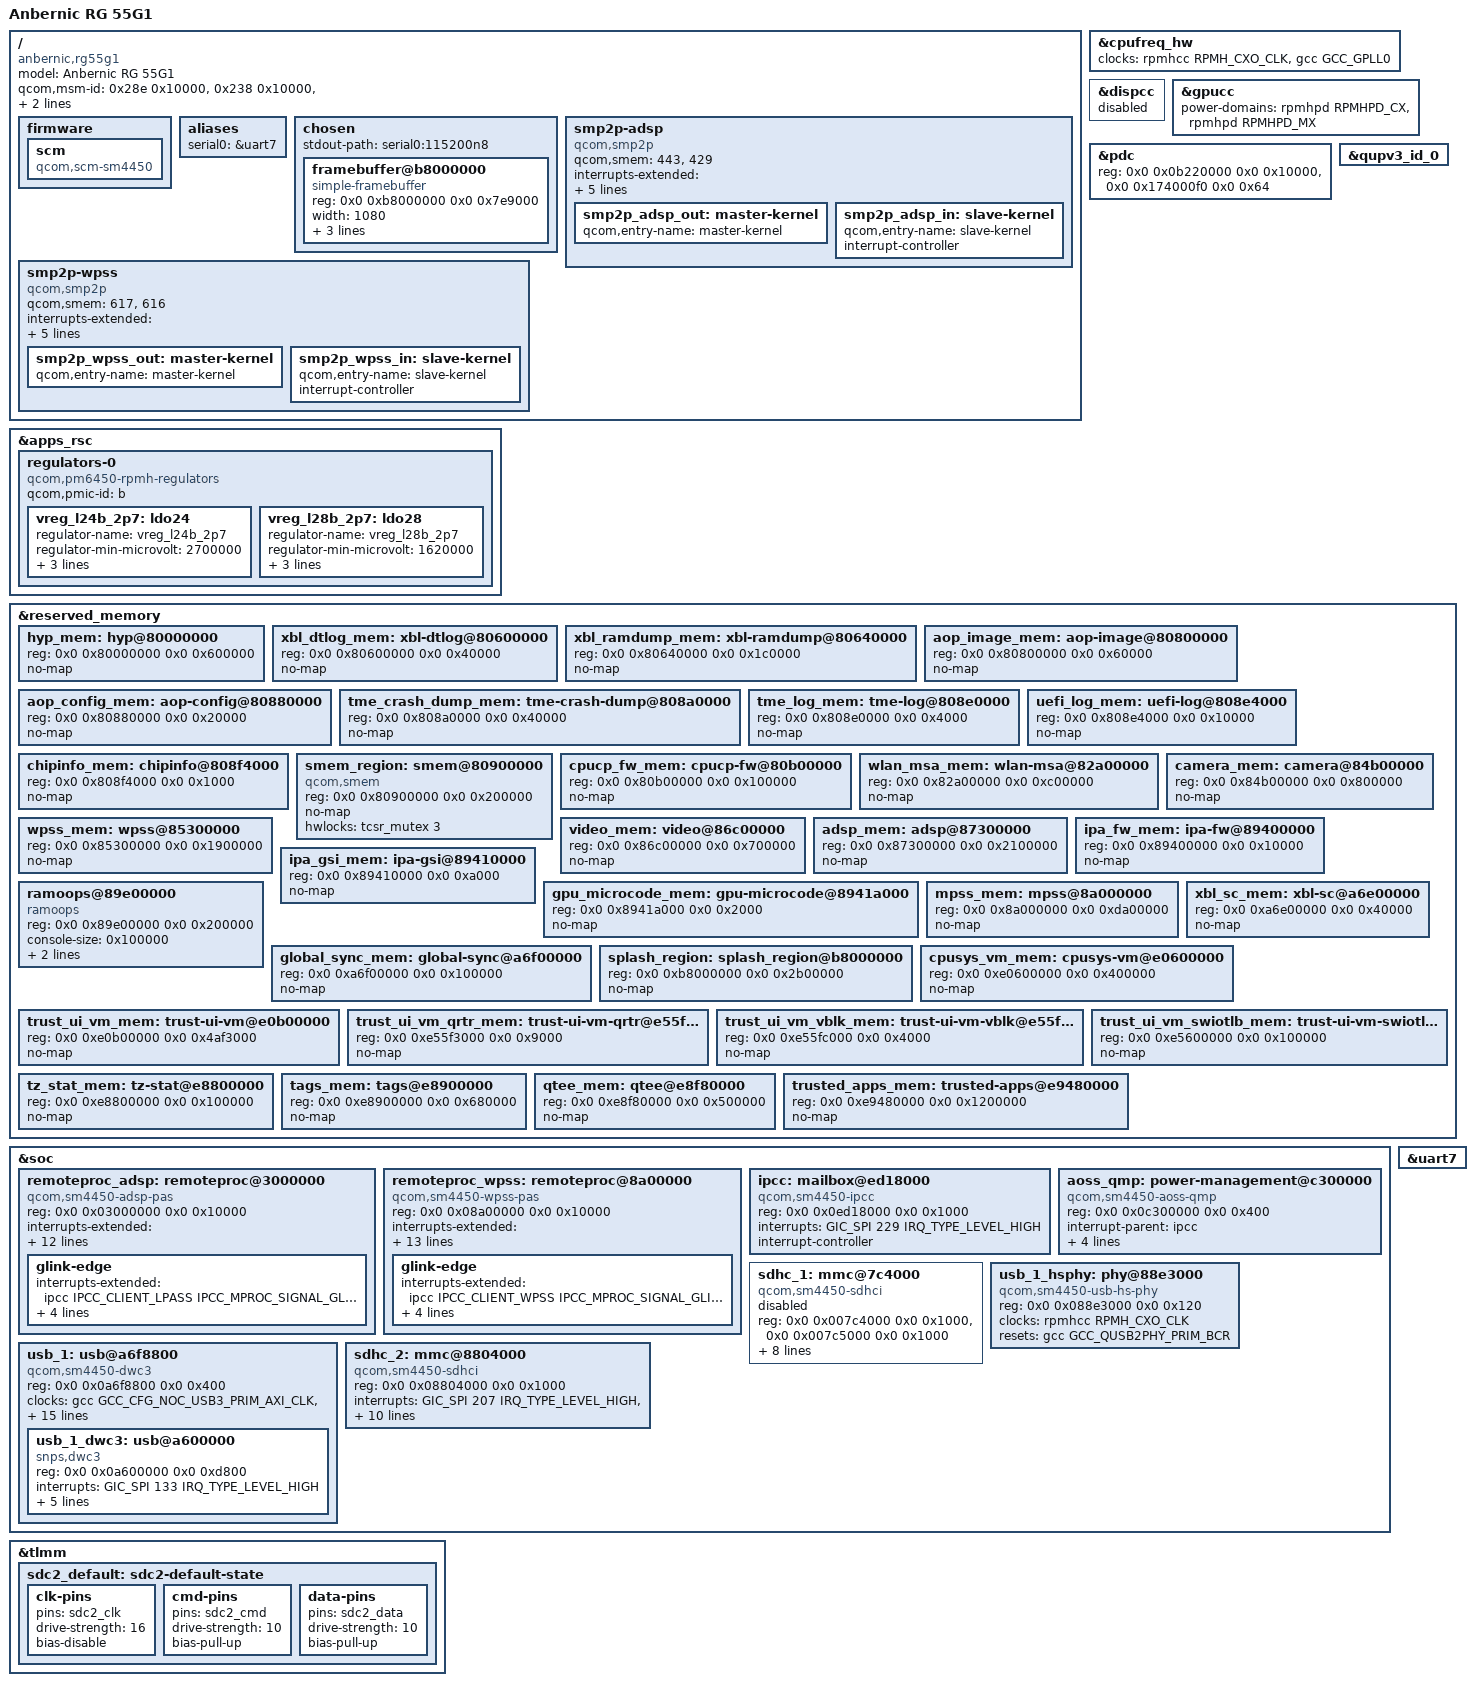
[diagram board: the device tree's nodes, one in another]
// SPDX-License-Identifier: BSD-3-Clause
/*
 * Anbernic RG 55G1 (SM4450)
 *
 * Hardware data from the stock DT in lualiliu's
 * RG55G1 linux tree (sg4250p-anbernic-rg55g1.dts, decompiled vendor DTB).
 */

/dts-v1/;

#include <dt-bindings/gpio/gpio.h>
#include <dt-bindings/mailbox/qcom-ipcc.h>
#include <dt-bindings/regulator/qcom,rpmh-regulator.h>
#include "sm4450.dtsi"
/ {
	model = "Anbernic RG 55G1";
	compatible = "anbernic,rg55g1", "qcom,sm4450";
	qcom,msm-id = <0x28e 0x10000>, <0x238 0x10000>, <0x25a 0x10000>;
	qcom,board-id = <0x1000b 0>;

	firmware {
		scm: scm {
			compatible = "qcom,scm-sm4450", "qcom,scm";
		};
	};

	aliases {
		serial0 = &uart7;
	};

	chosen {
		#address-cells = <2>;
		#size-cells = <2>;
		ranges;
		stdout-path = "serial0:115200n8";

		framebuffer@b8000000 {
			compatible = "simple-framebuffer";
			reg = <0x0 0xb8000000 0x0 0x7e9000>;
			width = <1080>;
			height = <1920>;
			stride = <4320>;
			format = "x8r8g8b8";
			status = "okay";
		};
	};

	smp2p-adsp {
		compatible = "qcom,smp2p";
		qcom,smem = <443>, <429>;
		interrupts-extended = <&ipcc IPCC_CLIENT_LPASS
					     IPCC_MPROC_SIGNAL_SMP2P
					     IRQ_TYPE_EDGE_RISING>;
		mboxes = <&ipcc IPCC_CLIENT_LPASS IPCC_MPROC_SIGNAL_SMP2P>;
		qcom,local-pid = <0>;
		qcom,remote-pid = <2>;

		smp2p_adsp_out: master-kernel {
			qcom,entry-name = "master-kernel";
			#qcom,smem-state-cells = <1>;
		};

		smp2p_adsp_in: slave-kernel {
			qcom,entry-name = "slave-kernel";
			interrupt-controller;
			#interrupt-cells = <2>;
		};
	};

	smp2p-wpss {
		compatible = "qcom,smp2p";
		qcom,smem = <617>, <616>;
		interrupts-extended = <&ipcc IPCC_CLIENT_WPSS
					     IPCC_MPROC_SIGNAL_SMP2P
					     IRQ_TYPE_EDGE_RISING>;
		mboxes = <&ipcc IPCC_CLIENT_WPSS IPCC_MPROC_SIGNAL_SMP2P>;
		qcom,local-pid = <0>;
		qcom,remote-pid = <13>;

		smp2p_wpss_out: master-kernel {
			qcom,entry-name = "master-kernel";
			#qcom,smem-state-cells = <1>;
		};

		smp2p_wpss_in: slave-kernel {
			qcom,entry-name = "slave-kernel";
			interrupt-controller;
			#interrupt-cells = <2>;
		};
	};
};

&apps_rsc {
	regulators-0 {
		compatible = "qcom,pm6450-rpmh-regulators";
		qcom,pmic-id = "b";

		vreg_l24b_2p7: ldo24 {
			regulator-name = "vreg_l24b_2p7";
			regulator-min-microvolt = <2700000>;
			regulator-max-microvolt = <3544000>;
			regulator-initial-mode = <RPMH_REGULATOR_MODE_HPM>;
		};

		vreg_l28b_2p7: ldo28 {
			regulator-name = "vreg_l28b_2p7";
			regulator-min-microvolt = <1620000>;
			regulator-max-microvolt = <3300000>;
			regulator-initial-mode = <RPMH_REGULATOR_MODE_HPM>;
		};
	};
};

&cpufreq_hw {
	clocks = <&rpmhcc RPMH_CXO_CLK>, <&gcc GCC_GPLL0>;
};

/* TODO: revert this dispcc */
&dispcc {
	status = "disabled";
};

&gpucc {
	power-domains = <&rpmhpd RPMHPD_CX>,
			<&rpmhpd RPMHPD_MX>;
};

&pdc {
	reg = <0x0 0x0b220000 0x0 0x10000>, <0x0 0x174000f0 0x0 0x64>;
};

&qupv3_id_0 {
	status = "okay";
};

&reserved_memory {
	hyp_mem: hyp@80000000 {
		reg = <0x0 0x80000000 0x0 0x600000>;
		no-map;
	};

	xbl_dtlog_mem: xbl-dtlog@80600000 {
		reg = <0x0 0x80600000 0x0 0x40000>;
		no-map;
	};

	xbl_ramdump_mem: xbl-ramdump@80640000 {
		reg = <0x0 0x80640000 0x0 0x1c0000>;
		no-map;
	};

	aop_image_mem: aop-image@80800000 {
		reg = <0x0 0x80800000 0x0 0x60000>;
		no-map;
	};

	aop_config_mem: aop-config@80880000 {
		reg = <0x0 0x80880000 0x0 0x20000>;
		no-map;
	};

	tme_crash_dump_mem: tme-crash-dump@808a0000 {
		reg = <0x0 0x808a0000 0x0 0x40000>;
		no-map;
	};

	tme_log_mem: tme-log@808e0000 {
		reg = <0x0 0x808e0000 0x0 0x4000>;
		no-map;
	};

	uefi_log_mem: uefi-log@808e4000 {
		reg = <0x0 0x808e4000 0x0 0x10000>;
		no-map;
	};

	chipinfo_mem: chipinfo@808f4000 {
		reg = <0x0 0x808f4000 0x0 0x1000>;
		no-map;
	};

	smem_region: smem@80900000 {
		compatible = "qcom,smem";
		reg = <0x0 0x80900000 0x0 0x200000>;
		no-map;
		hwlocks = <&tcsr_mutex 3>;
	};

	cpucp_fw_mem: cpucp-fw@80b00000 {
		reg = <0x0 0x80b00000 0x0 0x100000>;
		no-map;
	};

	wlan_msa_mem: wlan-msa@82a00000 {
		reg = <0x0 0x82a00000 0x0 0xc00000>;
		no-map;
	};

	camera_mem: camera@84b00000 {
		reg = <0x0 0x84b00000 0x0 0x800000>;
		no-map;
	};

	wpss_mem: wpss@85300000 {
		reg = <0x0 0x85300000 0x0 0x1900000>;
		no-map;
	};

	video_mem: video@86c00000 {
		reg = <0x0 0x86c00000 0x0 0x700000>;
		no-map;
	};

	adsp_mem: adsp@87300000 {
		reg = <0x0 0x87300000 0x0 0x2100000>;
		no-map;
	};

	ipa_fw_mem: ipa-fw@89400000 {
		reg = <0x0 0x89400000 0x0 0x10000>;
		no-map;
	};

	ipa_gsi_mem: ipa-gsi@89410000 {
		reg = <0x0 0x89410000 0x0 0xa000>;
		no-map;
	};

	gpu_microcode_mem: gpu-microcode@8941a000 {
		reg = <0x0 0x8941a000 0x0 0x2000>;
		no-map;
	};

	ramoops@89e00000 {
		compatible = "ramoops";
		reg = <0x0 0x89e00000 0x0 0x200000>;
		console-size = <0x100000>;
		record-size = <0x20000>;
		pmsg-size = <0x20000>;
	};

	mpss_mem: mpss@8a000000 {
		reg = <0x0 0x8a000000 0x0 0xda00000>;
		no-map;
	};

	xbl_sc_mem: xbl-sc@a6e00000 {
		reg = <0x0 0xa6e00000 0x0 0x40000>;
		no-map;
	};

	global_sync_mem: global-sync@a6f00000 {
		reg = <0x0 0xa6f00000 0x0 0x100000>;
		no-map;
	};

	splash_region: splash_region@b8000000 {
		reg = <0x0 0xb8000000 0x0 0x2b00000>;
		no-map;
	};

	cpusys_vm_mem: cpusys-vm@e0600000 {
		reg = <0x0 0xe0600000 0x0 0x400000>;
		no-map;
	};

	trust_ui_vm_mem: trust-ui-vm@e0b00000 {
		reg = <0x0 0xe0b00000 0x0 0x4af3000>;
		no-map;
	};

	trust_ui_vm_qrtr_mem: trust-ui-vm-qrtr@e55f3000 {
		reg = <0x0 0xe55f3000 0x0 0x9000>;
		no-map;
	};

	trust_ui_vm_vblk_mem: trust-ui-vm-vblk@e55fc000 {
		reg = <0x0 0xe55fc000 0x0 0x4000>;
		no-map;
	};

	trust_ui_vm_swiotlb_mem: trust-ui-vm-swiotlb@e5600000 {
		reg = <0x0 0xe5600000 0x0 0x100000>;
		no-map;
	};

	tz_stat_mem: tz-stat@e8800000 {
		reg = <0x0 0xe8800000 0x0 0x100000>;
		no-map;
	};

	tags_mem: tags@e8900000 {
		reg = <0x0 0xe8900000 0x0 0x680000>;
		no-map;
	};

	qtee_mem: qtee@e8f80000 {
		reg = <0x0 0xe8f80000 0x0 0x500000>;
		no-map;
	};

	trusted_apps_mem: trusted-apps@e9480000 {
		reg = <0x0 0xe9480000 0x0 0x1200000>;
		no-map;
	};
};

&soc {
	remoteproc_adsp: remoteproc@3000000 {
		compatible = "qcom,sm4450-adsp-pas";
		reg = <0x0 0x03000000 0x0 0x10000>;

		interrupts-extended = <&pdc 6 IRQ_TYPE_EDGE_RISING>,
				      <&smp2p_adsp_in 0 IRQ_TYPE_EDGE_RISING>,
				      <&smp2p_adsp_in 1 IRQ_TYPE_EDGE_RISING>,
				      <&smp2p_adsp_in 2 IRQ_TYPE_EDGE_RISING>,
				      <&smp2p_adsp_in 3 IRQ_TYPE_EDGE_RISING>;
		interrupt-names = "wdog", "fatal", "ready",
				  "handover", "stop-ack";

		clocks = <&rpmhcc RPMH_CXO_CLK>;
		clock-names = "xo";

		power-domains = <&rpmhpd RPMHPD_CX>;
		power-domain-names = "cx";

		memory-region = <&adsp_mem>;

		qcom,qmp = <&aoss_qmp>;
		qcom,smem-states = <&smp2p_adsp_out 0>;
		qcom,smem-state-names = "stop";

		firmware-name = "qcom/sm4450/adsp.mbn";

		/* TODO: audio - stock uses AudioReach (gpr/q6apm), no
		 * mainline sm4450 machine driver yet */
		glink-edge {
			interrupts-extended = <&ipcc IPCC_CLIENT_LPASS
						     IPCC_MPROC_SIGNAL_GLINK_QMP
						     IRQ_TYPE_EDGE_RISING>;
			mboxes = <&ipcc IPCC_CLIENT_LPASS
					IPCC_MPROC_SIGNAL_GLINK_QMP>;
			label = "lpass";
			qcom,remote-pid = <2>;
		};
	};

	remoteproc_wpss: remoteproc@8a00000 {
		compatible = "qcom,sm4450-wpss-pas";
		reg = <0x0 0x08a00000 0x0 0x10000>;

		interrupts-extended = <&intc GIC_SPI 587 IRQ_TYPE_EDGE_RISING>,
				      <&smp2p_wpss_in 0 IRQ_TYPE_EDGE_RISING>,
				      <&smp2p_wpss_in 1 IRQ_TYPE_EDGE_RISING>,
				      <&smp2p_wpss_in 2 IRQ_TYPE_EDGE_RISING>,
				      <&smp2p_wpss_in 3 IRQ_TYPE_EDGE_RISING>;
		interrupt-names = "wdog", "fatal", "ready",
				  "handover", "stop-ack";

		clocks = <&rpmhcc RPMH_CXO_CLK>;
		clock-names = "xo";

		power-domains = <&rpmhpd RPMHPD_CX>,
				<&rpmhpd RPMHPD_MX>;
		power-domain-names = "cx", "mx";

		memory-region = <&wpss_mem>;

		qcom,qmp = <&aoss_qmp>;
		qcom,smem-states = <&smp2p_wpss_out 0>;
		qcom,smem-state-names = "stop";

		firmware-name = "qcom/sm4450/wpss.mbn";

		/* TODO: ath11k WCN6750 (?) node */
		glink-edge {
			interrupts-extended = <&ipcc IPCC_CLIENT_WPSS
						     IPCC_MPROC_SIGNAL_GLINK_QMP
						     IRQ_TYPE_EDGE_RISING>;
			mboxes = <&ipcc IPCC_CLIENT_WPSS
					IPCC_MPROC_SIGNAL_GLINK_QMP>;
			label = "wpss";
			qcom,remote-pid = <13>;
		};
	};

	ipcc: mailbox@ed18000 {
		compatible = "qcom,sm4450-ipcc", "qcom,ipcc";
		reg = <0x0 0x0ed18000 0x0 0x1000>;
		interrupts = <GIC_SPI 229 IRQ_TYPE_LEVEL_HIGH>;
		interrupt-controller;
		#interrupt-cells = <3>;
		#mbox-cells = <2>;
	};

	aoss_qmp: power-management@c300000 {
		compatible = "qcom,sm4450-aoss-qmp", "qcom,aoss-qmp";
		reg = <0x0 0x0c300000 0x0 0x400>;
		interrupt-parent = <&ipcc>;
		interrupts-extended = <&ipcc IPCC_CLIENT_AOP
					     IPCC_MPROC_SIGNAL_GLINK_QMP
					     IRQ_TYPE_EDGE_RISING>;
		mboxes = <&ipcc IPCC_CLIENT_AOP IPCC_MPROC_SIGNAL_GLINK_QMP>;
		#clock-cells = <0>;
	};

	sdhc_1: mmc@7c4000 {
		compatible = "qcom,sm4450-sdhci", "qcom,sdhci-msm-v5";
		reg = <0x0 0x007c4000 0x0 0x1000>,
		      <0x0 0x007c5000 0x0 0x1000>;
		reg-names = "hc", "cqhci";
		interrupts = <GIC_SPI 135 IRQ_TYPE_LEVEL_HIGH>,
			     <GIC_SPI 137 IRQ_TYPE_LEVEL_HIGH>;
		interrupt-names = "hc_irq", "pwr_irq";
		clocks = <&gcc GCC_SDCC1_AHB_CLK>,
			 <&gcc GCC_SDCC1_APPS_CLK>,
			 <&rpmhcc RPMH_CXO_CLK>;
		clock-names = "iface", "core", "xo";
		power-domains = <&rpmhpd RPMHPD_CX>;
		bus-width = <8>;
		supports-cqe;
		non-removable;
		status = "disabled";
	};

	usb_1_hsphy: phy@88e3000 {
		compatible = "qcom,sm4450-usb-hs-phy",
			     "qcom,usb-snps-hs-7nm-phy";
		reg = <0x0 0x088e3000 0x0 0x120>;
		#phy-cells = <0>;
		clocks = <&rpmhcc RPMH_CXO_CLK>;
		clock-names = "ref";
		resets = <&gcc GCC_QUSB2PHY_PRIM_BCR>;
	};

	usb_1: usb@a6f8800 {
		compatible = "qcom,sm4450-dwc3", "qcom,dwc3";
		reg = <0x0 0x0a6f8800 0x0 0x400>;
		#address-cells = <2>;
		#size-cells = <2>;
		ranges;

		clocks = <&gcc GCC_CFG_NOC_USB3_PRIM_AXI_CLK>,
			 <&gcc GCC_USB30_PRIM_MASTER_CLK>,
			 <&gcc GCC_AGGRE_USB3_PRIM_AXI_CLK>,
			 <&gcc GCC_USB30_PRIM_SLEEP_CLK>,
			 <&gcc GCC_USB30_PRIM_MOCK_UTMI_CLK>;
		clock-names = "cfg_noc",
			      "core",
			      "iface",
			      "sleep",
			      "mock_utmi";

		assigned-clocks = <&gcc GCC_USB30_PRIM_MOCK_UTMI_CLK>,
				  <&gcc GCC_USB30_PRIM_MASTER_CLK>;
		assigned-clock-rates = <19200000>, <133333333>;

		interrupts-extended = <&intc GIC_SPI 130 IRQ_TYPE_LEVEL_HIGH>,
				      <&pdc 14 IRQ_TYPE_EDGE_BOTH>,
				      <&pdc 15 IRQ_TYPE_EDGE_BOTH>,
				      <&pdc 17 IRQ_TYPE_LEVEL_HIGH>;
		interrupt-names = "pwr_event",
				  "dp_hs_phy_irq",
				  "dm_hs_phy_irq",
				  "ss_phy_irq";

		power-domains = <&gcc GCC_USB30_PRIM_GDSC>;

		resets = <&gcc GCC_USB30_PRIM_BCR>;

		usb_1_dwc3: usb@a600000 {
			compatible = "snps,dwc3";
			reg = <0x0 0x0a600000 0x0 0xd800>;
			interrupts = <GIC_SPI 133 IRQ_TYPE_LEVEL_HIGH>;
			snps,dis_u2_susphy_quirk;
			snps,dis_enblslpm_quirk;
			phys = <&usb_1_hsphy>;
			phy-names = "usb2-phy";
			/* TODO: HS only for now */
			maximum-speed = "high-speed";
			/* TODO: role switch via tcpm once PD controller is wired */
			dr_mode = "peripheral";
		};
	};

	sdhc_2: mmc@8804000 {
		compatible = "qcom,sm4450-sdhci", "qcom,sdhci-msm-v5";
		reg = <0x0 0x08804000 0x0 0x1000>;
		reg-names = "hc";
		interrupts = <GIC_SPI 207 IRQ_TYPE_LEVEL_HIGH>,
			     <GIC_SPI 223 IRQ_TYPE_LEVEL_HIGH>;
		interrupt-names = "hc_irq", "pwr_irq";
		clocks = <&gcc GCC_SDCC2_AHB_CLK>,
			 <&gcc GCC_SDCC2_APPS_CLK>,
			 <&rpmhcc RPMH_CXO_CLK>;
		clock-names = "iface", "core", "xo";
		power-domains = <&rpmhpd RPMHPD_CX>;
		pinctrl-0 = <&sdc2_default>;
		pinctrl-names = "default";
		vmmc-supply = <&vreg_l24b_2p7>;
		vqmmc-supply = <&vreg_l28b_2p7>;
		bus-width = <4>;
		cd-gpios = <&tlmm 101 GPIO_ACTIVE_LOW>;
		no-sdio;
		status = "okay";
	};
};

&tlmm {
	sdc2_default: sdc2-default-state {
		clk-pins {
			pins = "sdc2_clk";
			drive-strength = <16>;
			bias-disable;
		};

		cmd-pins {
			pins = "sdc2_cmd";
			drive-strength = <10>;
			bias-pull-up;
		};

		data-pins {
			pins = "sdc2_data";
			drive-strength = <10>;
			bias-pull-up;
		};
	};
};

&uart7 {
	status = "okay";
};
